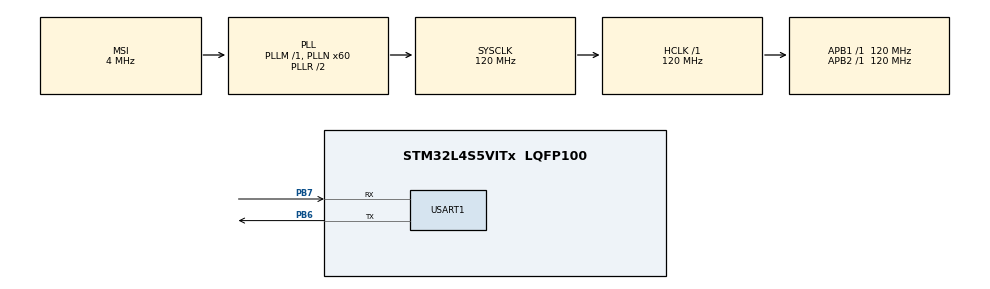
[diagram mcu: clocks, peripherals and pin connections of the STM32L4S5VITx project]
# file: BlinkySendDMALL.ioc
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Dma.Request0=USART1_TX
Dma.USART1_TX.0.Direction=DMA_MEMORY_TO_PERIPH
Dma.USART1_TX.0.EventEnable=DISABLE
Dma.USART1_TX.0.Instance=DMA1_Channel1
Dma.USART1_TX.0.MemDataAlignment=DMA_MDATAALIGN_BYTE
Dma.USART1_TX.0.MemInc=DMA_MINC_ENABLE
Dma.USART1_TX.0.Mode=DMA_NORMAL
Dma.USART1_TX.0.PeriphDataAlignment=DMA_PDATAALIGN_BYTE
Dma.USART1_TX.0.PeriphInc=DMA_PINC_DISABLE
Dma.USART1_TX.0.Polarity=HAL_DMAMUX_REQUEST_GEN_RISING
Dma.USART1_TX.0.Priority=DMA_PRIORITY_MEDIUM
Dma.USART1_TX.0.RequestNumber=1
Dma.USART1_TX.0.SignalID=NONE
Dma.USART1_TX.0.SyncEnable=DISABLE
Dma.USART1_TX.0.SyncPolarity=HAL_DMAMUX_SYNC_NO_EVENT
Dma.USART1_TX.0.SyncRequestNumber=1
Dma.USART1_TX.0.SyncSignalID=NONE
Mcu.Family=STM32L4
Mcu.Name=STM32L4S5VITx
Mcu.Package=LQFP100
NVIC.DMA1_Channel1_IRQn=true\:0\:0\:false\:false\:true\:false\:true\:true
NVIC.PriorityGroup=NVIC_PRIORITYGROUP_4
NVIC.USART1_IRQn=true\:0\:0\:false\:false\:true\:true\:true\:true
PB6.Mode=Asynchronous
PB6.Signal=USART1_TX
PB7.Mode=Asynchronous
PB7.Signal=USART1_RX
ProjectManager.HeapSize=0x200
ProjectManager.StackSize=0x400
ProjectManager.TargetToolchain=STM32CubeIDE
RCC.AHBFreq_Value=120000000
RCC.APB1Freq_Value=120000000
RCC.APB1TimFreq_Value=120000000
RCC.APB2Freq_Value=120000000
RCC.APB2TimFreq_Value=120000000
RCC.CortexFreq_Value=120000000
RCC.HCLKFreq_Value=120000000
RCC.HSE_VALUE=8000000
RCC.HSI48_VALUE=48000000
RCC.HSI_VALUE=16000000
RCC.LSE_VALUE=32768
RCC.MSI_VALUE=4000000
RCC.PLLN=60
RCC.SYSCLKFreq_VALUE=120000000
RCC.SYSCLKSource=RCC_SYSCLKSOURCE_PLLCLK
RCC.VCOOutputFreq_Value=240000000
USART1.VirtualMode-Asynchronous=VM_ASYNC
board=custom

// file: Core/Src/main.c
/* USER CODE BEGIN Header */
/**
  ******************************************************************************
  * @file           : main.c
  * @brief          : Main program body
  ******************************************************************************
  * @attention
  *
  * Copyright (c) 2023 STMicroelectronics.
  * All rights reserved.
  *
  * This software is licensed under terms that can be found in the LICENSE file
  * in the root directory of this software component.
  * If no LICENSE file comes with this software, it is provided AS-IS.
  *
  ******************************************************************************
  */
/* USER CODE END Header */
#include "main.h"

/* USER CODE BEGIN Includes */
#include "data.h"
/* USER CODE END Includes */

void SystemClock_Config(void);
static void MX_GPIO_Init(void);
static void MX_DMA_Init(void);
static void MX_USART1_UART_Init(void);
/* USER CODE BEGIN PFP */
void BlinkySendDMA(void); //sends a copy of its own main.c (text) to the PC
/* USER CODE END PFP */

int main(void)
{

  /* MCU Configuration--------------------------------------------------------*/

  /* Reset of all peripherals, Initializes the Flash interface and the Systick. */
  HAL_Init();

  /* Configure the system clock */
  SystemClock_Config();

  /* Initialize all configured peripherals */
  MX_GPIO_Init();
  MX_DMA_Init();
  MX_USART1_UART_Init();
  /* USER CODE BEGIN 2 */
  BlinkySendDMA();
  /* USER CODE END 2 */

  /* Infinite loop */
  while (1)
  {

  }
}

void SystemClock_Config(void)
{
  RCC_OscInitTypeDef RCC_OscInitStruct = {0};
  RCC_ClkInitTypeDef RCC_ClkInitStruct = {0};

  /** Configure the main internal regulator output voltage
  */
  if (HAL_PWREx_ControlVoltageScaling(PWR_REGULATOR_VOLTAGE_SCALE1_BOOST) != HAL_OK)
  {
    Error_Handler();
  }

  /** Initializes the RCC Oscillators according to the specified parameters
  * in the RCC_OscInitTypeDef structure.
  */
  RCC_OscInitStruct.OscillatorType = RCC_OSCILLATORTYPE_MSI;
  RCC_OscInitStruct.MSIState = RCC_MSI_ON;
  RCC_OscInitStruct.MSICalibrationValue = 0;
  RCC_OscInitStruct.MSIClockRange = RCC_MSIRANGE_6;
  RCC_OscInitStruct.PLL.PLLState = RCC_PLL_ON;
  RCC_OscInitStruct.PLL.PLLSource = RCC_PLLSOURCE_MSI;
  RCC_OscInitStruct.PLL.PLLM = 1;
  RCC_OscInitStruct.PLL.PLLN = 60;
  RCC_OscInitStruct.PLL.PLLP = RCC_PLLP_DIV2;
  RCC_OscInitStruct.PLL.PLLQ = RCC_PLLQ_DIV2;
  RCC_OscInitStruct.PLL.PLLR = RCC_PLLR_DIV2;
  if (HAL_RCC_OscConfig(&RCC_OscInitStruct) != HAL_OK)
  {
    Error_Handler();
  }

  /** Initializes the CPU, AHB and APB buses clocks
  */
  RCC_ClkInitStruct.ClockType = RCC_CLOCKTYPE_HCLK|RCC_CLOCKTYPE_SYSCLK
                              |RCC_CLOCKTYPE_PCLK1|RCC_CLOCKTYPE_PCLK2;
  RCC_ClkInitStruct.SYSCLKSource = RCC_SYSCLKSOURCE_PLLCLK;
  RCC_ClkInitStruct.AHBCLKDivider = RCC_SYSCLK_DIV1;
  RCC_ClkInitStruct.APB1CLKDivider = RCC_HCLK_DIV1;
  RCC_ClkInitStruct.APB2CLKDivider = RCC_HCLK_DIV1;

  if (HAL_RCC_ClockConfig(&RCC_ClkInitStruct, FLASH_LATENCY_5) != HAL_OK)
  {
    Error_Handler();
  }
}

static void MX_USART1_UART_Init(void)
{

  LL_USART_InitTypeDef USART_InitStruct = {0};

  LL_GPIO_InitTypeDef GPIO_InitStruct = {0};
  RCC_PeriphCLKInitTypeDef PeriphClkInit = {0};

  /** Initializes the peripherals clock
  */
  PeriphClkInit.PeriphClockSelection = RCC_PERIPHCLK_USART1;
  PeriphClkInit.Usart1ClockSelection = RCC_USART1CLKSOURCE_PCLK2;
  if (HAL_RCCEx_PeriphCLKConfig(&PeriphClkInit) != HAL_OK)
  {
    Error_Handler();
  }

  /* Peripheral clock enable */
  LL_APB2_GRP1_EnableClock(LL_APB2_GRP1_PERIPH_USART1);

  LL_AHB2_GRP1_EnableClock(LL_AHB2_GRP1_PERIPH_GPIOB);
  /**USART1 GPIO Configuration
  PB6   ------> USART1_TX
  PB7   ------> USART1_RX
  */
  GPIO_InitStruct.Pin = LL_GPIO_PIN_6|LL_GPIO_PIN_7;
  GPIO_InitStruct.Mode = LL_GPIO_MODE_ALTERNATE;
  GPIO_InitStruct.Speed = LL_GPIO_SPEED_FREQ_VERY_HIGH;
  GPIO_InitStruct.OutputType = LL_GPIO_OUTPUT_PUSHPULL;
  GPIO_InitStruct.Pull = LL_GPIO_PULL_NO;
  GPIO_InitStruct.Alternate = LL_GPIO_AF_7;
  LL_GPIO_Init(GPIOB, &GPIO_InitStruct);

  /* USART1 DMA Init */

  /* USART1_TX Init */
  LL_DMA_SetPeriphRequest(DMA1, LL_DMA_CHANNEL_1, LL_DMAMUX_REQ_USART1_TX);

  LL_DMA_SetDataTransferDirection(DMA1, LL_DMA_CHANNEL_1, LL_DMA_DIRECTION_MEMORY_TO_PERIPH);

  LL_DMA_SetChannelPriorityLevel(DMA1, LL_DMA_CHANNEL_1, LL_DMA_PRIORITY_MEDIUM);

  LL_DMA_SetMode(DMA1, LL_DMA_CHANNEL_1, LL_DMA_MODE_NORMAL);

  LL_DMA_SetPeriphIncMode(DMA1, LL_DMA_CHANNEL_1, LL_DMA_PERIPH_NOINCREMENT);

  LL_DMA_SetMemoryIncMode(DMA1, LL_DMA_CHANNEL_1, LL_DMA_MEMORY_INCREMENT);

  LL_DMA_SetPeriphSize(DMA1, LL_DMA_CHANNEL_1, LL_DMA_PDATAALIGN_BYTE);

  LL_DMA_SetMemorySize(DMA1, LL_DMA_CHANNEL_1, LL_DMA_MDATAALIGN_BYTE);

  /* USART1 interrupt Init */
  NVIC_SetPriority(USART1_IRQn, NVIC_EncodePriority(NVIC_GetPriorityGrouping(),0, 0));
  NVIC_EnableIRQ(USART1_IRQn);

  USART_InitStruct.PrescalerValue = LL_USART_PRESCALER_DIV1;
  USART_InitStruct.BaudRate = 115200;
  USART_InitStruct.DataWidth = LL_USART_DATAWIDTH_8B;
  USART_InitStruct.StopBits = LL_USART_STOPBITS_1;
  USART_InitStruct.Parity = LL_USART_PARITY_NONE;
  USART_InitStruct.TransferDirection = LL_USART_DIRECTION_TX_RX;
  USART_InitStruct.HardwareFlowControl = LL_USART_HWCONTROL_NONE;
  USART_InitStruct.OverSampling = LL_USART_OVERSAMPLING_16;
  LL_USART_Init(USART1, &USART_InitStruct);
  LL_USART_SetTXFIFOThreshold(USART1, LL_USART_FIFOTHRESHOLD_1_8);
  LL_USART_SetRXFIFOThreshold(USART1, LL_USART_FIFOTHRESHOLD_1_8);
  LL_USART_DisableFIFO(USART1);
  LL_USART_ConfigAsyncMode(USART1);
  LL_USART_Enable(USART1);

}

static void MX_DMA_Init(void)
{

  /* Init with LL driver */
  /* DMA controller clock enable */
  LL_AHB1_GRP1_EnableClock(LL_AHB1_GRP1_PERIPH_DMAMUX1);
  LL_AHB1_GRP1_EnableClock(LL_AHB1_GRP1_PERIPH_DMA1);

  /* DMA interrupt init */
  /* DMA1_Channel1_IRQn interrupt configuration */
  NVIC_SetPriority(DMA1_Channel1_IRQn, NVIC_EncodePriority(NVIC_GetPriorityGrouping(),0, 0));
  NVIC_EnableIRQ(DMA1_Channel1_IRQn);

}

static void MX_GPIO_Init(void)
{

  /* GPIO Ports Clock Enable */
  __HAL_RCC_GPIOB_CLK_ENABLE();

}

/* USER CODE BEGIN 4 */
void BlinkySendDMA(void){
	LL_DMA_ConfigAddresses(DMA1, LL_DMA_CHANNEL_1, (uint32_t)main_c, LL_USART_DMA_GetRegAddr(USART1,LL_USART_DMA_REG_DATA_TRANSMIT), LL_DMA_DIRECTION_MEMORY_TO_PERIPH);
//	LL_DMA_SetMemoryAddress(DMA1, LL_DMA_CHANNEL_1, (uint32_t)&main_c);
//	LL_DMA_DisableChannel(DMA1, LL_DMA_CHANNEL_1);
	LL_DMA_SetDataLength(DMA1,LL_DMA_CHANNEL_1 , main_c_len);
	LL_DMA_EnableChannel(DMA1, LL_DMA_CHANNEL_1);
	LL_USART_EnableDMAReq_TX(USART1);
}
/* USER CODE END 4 */

void Error_Handler(void)
{
  __disable_irq();
  while (1)
  {
  }
}
